VERSION ""

NS_ :

BS_:

BU_:

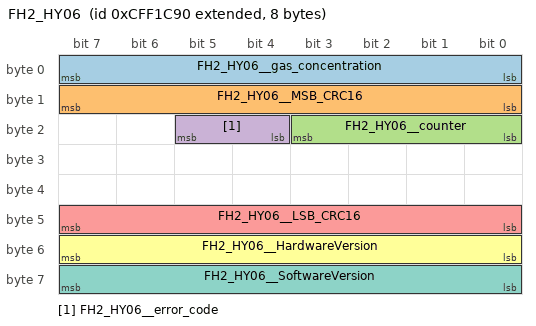
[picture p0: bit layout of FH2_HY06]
BO_ 2365529232 FH2_HY06: 8 Vector__XXX
 SG_ FH2_HY06__gas_concentration : 0|8@1+ (500,-5000) [0|20000] "ppm" Vector__XXX
 SG_ FH2_HY06__MSB_CRC16 : 8|8@1+ (1,0) [0|0] "" Vector__XXX
 SG_ FH2_HY06__counter : 16|4@1+ (1,0) [0|15] "" Vector__XXX
 SG_ FH2_HY06__error_code : 20|2@1+ (1,0) [0|0] "" Vector__XXX
 SG_ FH2_HY06__LSB_CRC16 : 40|8@1+ (1,0) [0|0] "" Vector__XXX
 SG_ FH2_HY06__HardwareVersion : 48|8@1+ (1,0) [0|0] "" Vector__XXX
 SG_ FH2_HY06__SoftwareVersion : 56|8@1+ (1,0) [0|0] "" Vector__XXX
